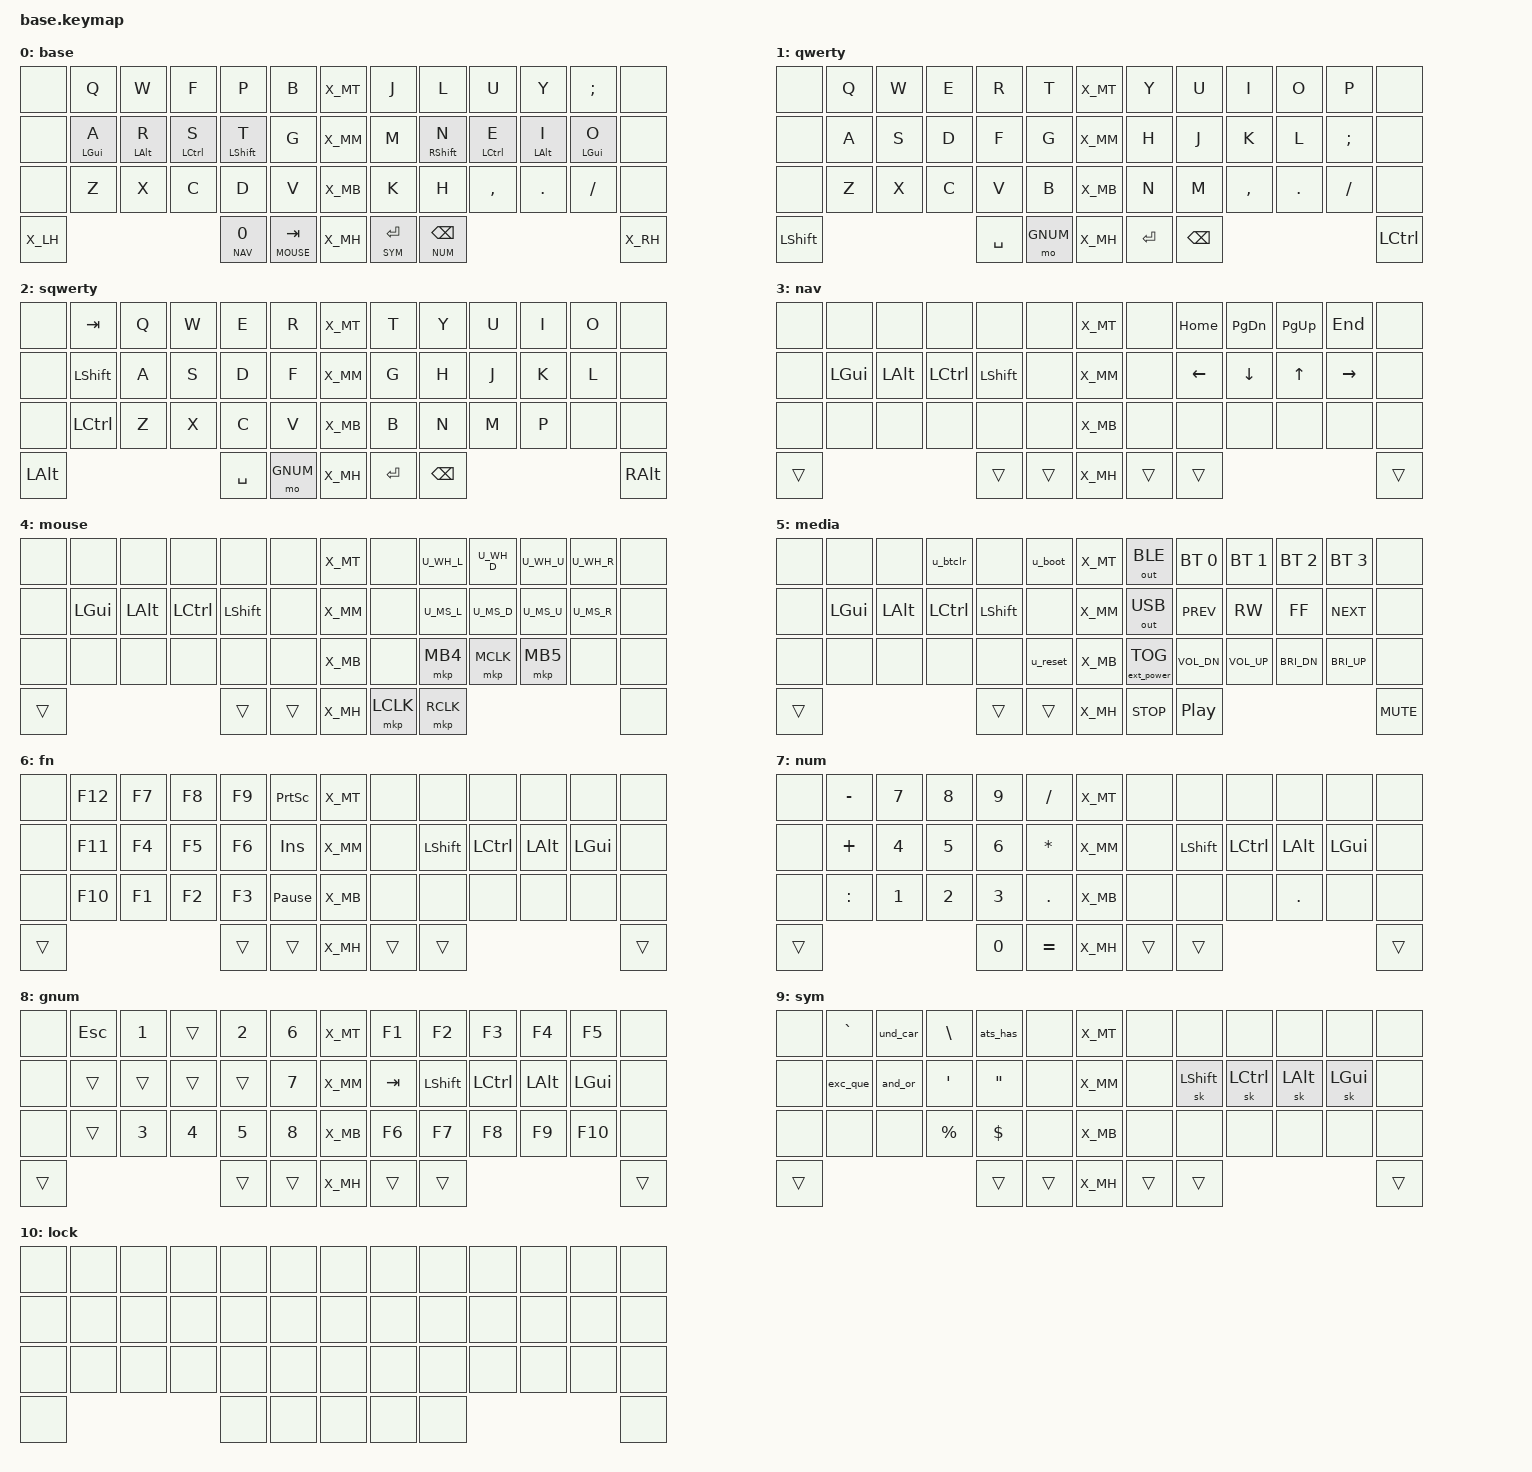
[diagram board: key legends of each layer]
#include <behaviors.dtsi>
#include <dt-bindings/zmk/keys.h>
#if CONFIG_WIRELESS
    #include <dt-bindings/zmk/bt.h>
    #define _BT_SEL_KEYS_ &bt BT_SEL 0 &bt BT_SEL 1 &bt BT_SEL 2 &bt BT_SEL 3 &bt BT_CLR
#else
    #define _BT_SEL_KEYS_ &trans &trans &trans &trans &trans
#endif

#include <dt-bindings/zmk/ext_power.h>
#include <dt-bindings/zmk/outputs.h>
#include "../zmk-nodefree-config/helper.h"
#include "../zmk-nodefree-config/international_chars/greek.dtsi"
#include "../zmk-nodefree-config/international_chars/german.dtsi"

#define DEF 0
#define QWERTY 1
#define SQWERTY 2
#define NAV 3
#define MOUSE 4
#define MEDIA 5
#define FN 6
#define NUM 7
#define GNUM 8
#define SYM 9
#define LOCK 10

#include "mouse.dtsi"
#include "extra_keys.h"

#define XXX &none
#define ___ &trans

/* Global settings */

#define QUICK_TAP_MS 175

&sk {  // sticky-key config
    release-after-ms = <900>;  // release after 0.6s
    quick-release;             // no double capitalization when rolling keys
};

&sl {  // sticky-layer config
    ignore-modifiers;          // allow chording sticky mods & layers
};

&lt {  // layer-tap config
    flavor = "balanced";
    tapping-term-ms = <200>;
    quick-tap-ms = <QUICK_TAP_MS>;
};

/* Homerow mods */

#define KEYS_L LT0 LT1 LT2 LT3 LT4 LM0 LM1 LM2 LM3 LM4 LB0 LB1 LB2 LB3 LB4  // left hand
#define KEYS_R RT0 RT1 RT2 RT3 RT4 RM0 RM1 RM2 RM3 RM4 RB0 RB1 RB2 RB3 RB4  // right hand
#define THUMBS LH2 LH1 LH0 RH0 RH1 RH2                                      // thumbs

#define MAKE_HRM(NAME, HOLD, TAP, TRIGGER_POS) \
    ZMK_BEHAVIOR(NAME, hold_tap, \
        flavor = "balanced"; \
        tapping-term-ms = <280>; \
        quick-tap-ms = <QUICK_TAP_MS>; \
        bindings = <HOLD>, <TAP>; \
        hold-trigger-key-positions = <TRIGGER_POS>; \
        hold-trigger-on-release; \
    )
MAKE_HRM(hml, &kp, &kp, KEYS_R THUMBS)  // left-hand HRMs
MAKE_HRM(hmr, &kp, &kp, KEYS_L THUMBS)  // right-hand HRMs

MAKE_HRM(hml_repeat, &kp, &key_repeat, KEYS_R THUMBS)  // used for HRM-combo
//MAKE_HRM(hmr_lpar_lt, &kp, &lpar_lt, KEYS_L THUMBS)    // "    "   "   "
//MAKE_HRM(hmr_rpar_gt, &kp, &rpar_gt, KEYS_L THUMBS)    // "    "   "   "

/* Caps-word, num-word and smart-mouse */

&caps_word {  // mods deactivate caps-word, requires PR #1441
    /delete-property/ ignore-modifiers;
};

// tap: num-word | double-tap: sticky num-layer | hold: num-layer
#define SMART_NUM &smart_num NUM 0
ZMK_BEHAVIOR(smart_num, hold_tap,
    flavor = "balanced";
    tapping-term-ms = <200>;
    quick-tap-ms = <QUICK_TAP_MS>;
    bindings = <&mo>, <&num_dance>;
)
ZMK_BEHAVIOR(num_dance, tap_dance,
    tapping-term-ms = <200>;
    bindings = <&num_word>, <&sl NUM>;  // reverse this for sticky-num on single tap
)
&num_word {  // num-word, requires PR #1441
    layers = <NUM>;
    continue-list = <BSPC DEL DOT COMMA PLUS MINUS STAR FSLH EQUAL COLON>;
};

// smart-mouse, requires PR #1366
ZMK_BEHAVIOR(smart_mouse, tri_state,
    bindings = <&tog MOUSE>, <&none>, <&tog MOUSE>;
    ignored-key-positions = <LT1 LT3 RT0 RT1 RT2 RT3 RT4 RM1 RM2 RM3 RB1 RB2 RB3 RH0 RH1>;
    ignored-layers = <MOUSE>;
)

/* Custom behaviors */

// mod_morphs
ZMK_BEHAVIOR(und_car, mod_morph,
    mods = <(MOD_LSFT|MOD_RSFT)>;
    bindings = <&kp UNDER>, <&kp CARET>;
)

ZMK_BEHAVIOR(and_or, mod_morph,
    mods = <(MOD_LSFT|MOD_RSFT)>;
    bindings = <&kp AMPS>, <&kp PIPE>;
)

ZMK_BEHAVIOR(tim_per, mod_morph,
    mods = <(MOD_LSFT|MOD_RSFT)>;
    bindings = <&kp STAR>, <&kp PRCNT>;
)

ZMK_BEHAVIOR(plu_min, mod_morph,
    mods = <(MOD_LSFT|MOD_RSFT)>;
    bindings = <&kp PLUS>, <&kp MINUS>;
)

ZMK_BEHAVIOR(exc_que, mod_morph,
    mods = <(MOD_LSFT|MOD_RSFT)>;
    bindings = <&kp EXCL>, <&kp QMARK>;
)

ZMK_BEHAVIOR(dap_sap, mod_morph,
    mods = <(MOD_LSFT|MOD_RSFT)>;
    bindings = <&kp DQT>, <&kp SQT>;
)

ZMK_BEHAVIOR(ats_has, mod_morph,
    mods = <(MOD_LSFT|MOD_RSFT)>;
    bindings = <&kp AT>, <&kp HASH>;
)
// /mod_morphs

// tap: space | shift + tap: dot -> space -> sticky shift | hold: activate layer
ZMK_BEHAVIOR(lt_spc, hold_tap,
    flavor = "balanced";
    tapping-term-ms = <200>;
    quick-tap-ms = <QUICK_TAP_MS>;
    bindings = <&mo>, <&spc_morph>;
)
ZMK_BEHAVIOR(spc_morph, mod_morph,
    bindings = <&kp SPACE>, <&dot_spc>;
    mods = <(MOD_LSFT|MOD_RSFT)>;
)
ZMK_BEHAVIOR(dot_spc, macro,
    wait-ms = <0>;
    tap-ms = <5>;
    bindings = <&kp DOT &kp SPACE &sk LSHFT>;
)
// double tap guards
ZMK_BEHAVIOR(u_btclr, tap_dance,
    tapping-term-ms = <200>;
    bindings = <&none>, <&bt BT_CLR>; 
)
ZMK_BEHAVIOR(u_boot, tap_dance,
    tapping-term-ms = <200>;
    bindings = <&none>, <&bootloader>; 
)
ZMK_BEHAVIOR(u_reset, tap_dance,
    tapping-term-ms = <200>;
    bindings = <&none>, <&sys_reset>; 
)



ZMK_BEHAVIOR(esc_alt, tap_dance,
    tapping-term-ms = <200>;
    bindings = <&kp ESC>, <&kp LALT>; 
)


#include "combos.dtsi"  // requires layer aliases and stuff

/* Keymap */

// ZMK_CONDITIONAL_LAYER(FN NUM, SYS)  // FN + NUM --> SYS use later :)

ZMK_LAYER(base,
//╭──────╮ ╭─────────────┬─────────────┬─────────────┬─────────────┬─────────────╮ ╭──────╮ ╭─────────────┬─────────────┬─────────────┬─────────────┬─────────────╮ ╭──────╮
    XXX      &kp Q         &kp W         &kp F         &kp P         &kp B           X_MT     &kp J         &kp L         &kp U         &kp Y         &kp SEMI        XXX 
//├──────┤ ├─────────────┼─────────────┼─────────────┼─────────────┼─────────────┤ ├──────┤ ├─────────────┼─────────────┼─────────────┼─────────────┼─────────────┤ ├──────┤
    XXX      &hml LGUI A   &hml LALT R   &hml LCTRL S  &hml LSHFT T  &kp G           X_MM     &kp M         &hmr RSHFT N  &hmr LCTRL E  &hmr LALT I   &hmr LGUI O     XXX 
//├──────┤ ├─────────────┼─────────────┼─────────────┼─────────────┼─────────────┤ ├──────┤ ├─────────────┼─────────────┼─────────────┼─────────────┼─────────────┤ ├──────┤
    XXX      &kp Z         &kp X         &kp C         &kp D         &kp V           X_MB     &kp K         &kp H         &kp COMMA     &kp DOT       &kp FSLH        XXX 
//├──────┤ ╰─────────────┼─────────────┴─────────────┼─────────────┼─────────────┤ ├──────┤ ├─────────────┼─────────────┼─────────────┴───────────────────────────╯ ├──────┤
    X_LH                                              &lt_spc NAV 0  &lt MOUSE TAB   X_MH     &lt SYM RET   &lt NUM BSPC                                              X_RH
//╰──────╯                                           ╰─────────────┴─────────────╯ ╰──────╯ ╰─────────────┴─────────────╯                                           ╰──────╯
)

ZMK_LAYER(qwerty,
//╭──────╮ ╭─────────────┬─────────────┬─────────────┬─────────────┬─────────────╮ ╭──────╮ ╭─────────────┬─────────────┬─────────────┬─────────────┬─────────────╮ ╭──────╮
    XXX      &kp Q         &kp W         &kp E         &kp R         &kp T           X_MT     &kp Y         &kp U         &kp I         &kp O         &kp P           XXX 
//├──────┤ ├─────────────┼─────────────┼─────────────┼─────────────┼─────────────┤ ├──────┤ ├─────────────┼─────────────┼─────────────┼─────────────┼─────────────┤ ├──────┤
    XXX      &kp A         &kp S         &kp D         &kp F         &kp G           X_MM     &kp H         &kp J         &kp K         &kp L         &kp SEMI        XXX 
//├──────┤ ├─────────────┼─────────────┼─────────────┼─────────────┼─────────────┤ ├──────┤ ├─────────────┼─────────────┼─────────────┼─────────────┼─────────────┤ ├──────┤
    XXX      &kp Z         &kp X         &kp C         &kp V         &kp B           X_MB     &kp N         &kp M         &kp COMMA     &kp DOT       &kp FSLH         XXX 
//├──────┤ ╰─────────────┼─────────────┴─────────────┼─────────────┼─────────────┤ ├──────┤ ├─────────────┼─────────────┼─────────────┴───────────────────────────╯ ├──────┤
    &kp LSHFT                                          &kp SPACE     &mo GNUM        X_MH      &kp RET      &kp BSPC                                                &kp LCTRL
//╰──────╯                                           ╰─────────────┴─────────────╯ ╰──────╯ ╰─────────────┴─────────────╯                                           ╰──────╯
)

ZMK_LAYER(sqwerty,
//╭──────╮ ╭─────────────┬─────────────┬─────────────┬─────────────┬─────────────╮ ╭──────╮ ╭─────────────┬─────────────┬─────────────┬─────────────┬─────────────╮ ╭──────╮
    XXX      &kp TAB       &kp Q         &kp W         &kp E         &kp R           X_MT     &kp T         &kp Y         &kp U         &kp I         &kp O           XXX 
//├──────┤ ├─────────────┼─────────────┼─────────────┼─────────────┼─────────────┤ ├──────┤ ├─────────────┼─────────────┼─────────────┼─────────────┼─────────────┤ ├──────┤
    XXX      &kp LSHFT     &kp A         &kp S         &kp D         &kp F           X_MM     &kp G         &kp H         &kp J         &kp K         &kp L           XXX 
//├──────┤ ├─────────────┼─────────────┼─────────────┼─────────────┼─────────────┤ ├──────┤ ├─────────────┼─────────────┼─────────────┼─────────────┼─────────────┤ ├──────┤
    XXX      &kp LCTRL     &kp Z         &kp X         &kp C         &kp V           X_MB     &kp B         &kp N         &kp M         &kp P         XXX             XXX
//├──────┤ ╰─────────────┼─────────────┴─────────────┼─────────────┼─────────────┤ ├──────┤ ├─────────────┼─────────────┼─────────────┴───────────────────────────╯ ├──────┤
    &kp LALT                                           &kp SPACE     &mo GNUM        X_MH      &kp RET      &kp BSPC                                                &kp RALT
//╰──────╯                                           ╰─────────────┴─────────────╯ ╰──────╯ ╰─────────────┴─────────────╯                                           ╰──────╯
)

ZMK_LAYER(nav,
//╭──────╮ ╭─────────────┬─────────────┬─────────────┬─────────────┬─────────────╮ ╭──────╮ ╭─────────────┬─────────────┬─────────────┬─────────────┬─────────────╮ ╭──────╮
    XXX      XXX           XXX           XXX           XXX           XXX             X_MT     XXX           &kp HOME      &kp PG_DN     &kp PG_UP     &kp END         XXX
//├──────┤ ├─────────────┼─────────────┼─────────────┼─────────────┼─────────────┤ ├──────┤ ├─────────────┼─────────────┼─────────────┼─────────────┼─────────────┤ ├──────┤
    XXX      &kp LGUI      &kp LALT      &kp LCTRL     &kp LSHFT     XXX             X_MM     XXX          &kp LEFT      &kp DOWN      &kp UP        &kp RIGHT       XXX
//├──────┤ ├─────────────┼─────────────┼─────────────┼─────────────┼─────────────┤ ├──────┤ ├─────────────┼─────────────┼─────────────┼─────────────┼─────────────┤ ├──────┤
    XXX      XXX           XXX           XXX           XXX           XXX             X_MB     XXX           XXX           XXX           XXX           XXX             XXX
//├──────┤ ╰─────────────┼─────────────┴─────────────┼─────────────┼─────────────┤ ├──────┤ ├─────────────┼─────────────┼─────────────┴───────────────────────────╯ ├──────┤
    ___                                                ___           ___             X_MH     ___           ___                                                       ___
//╰──────╯                                           ╰─────────────┴─────────────╯ ╰──────╯ ╰─────────────┴─────────────╯                                           ╰──────╯
)

ZMK_LAYER(mouse,
//╭──────╮ ╭─────────────┬─────────────┬─────────────┬─────────────┬─────────────╮ ╭──────╮ ╭─────────────┬─────────────┬─────────────┬─────────────┬─────────────╮ ╭──────╮
    XXX      XXX           XXX           XXX            XXX          XXX             X_MT     XXX           U_WH_L        U_WH_D        U_WH_U        U_WH_R          XXX
//├──────┤ ├─────────────┼─────────────┼─────────────┼─────────────┼─────────────┤ ├──────┤ ├─────────────┼─────────────┼─────────────┼─────────────┼─────────────┤ ├──────┤
    XXX      &kp LGUI      &kp LALT      &kp LCTRL     &kp LSHFT     XXX             X_MM     XXX           U_MS_L        U_MS_D        U_MS_U        U_MS_R          XXX 
//├──────┤ ├─────────────┼─────────────┼─────────────┼─────────────┼─────────────┤ ├──────┤ ├─────────────┼─────────────┼─────────────┼─────────────┼─────────────┤ ├─-────┤
    XXX      XXX           XXX           XXX           XXX           XXX             X_MB     XXX           &mkp MB4      &mkp MCLK      &mkp MB5     XXX             XXX 
//├──────┤ ╰─────────────┼─────────────┴─────────────┼─────────────┼─────────────┤ ├──────┤ ├─────────────┼─────────────┼─────────────┴───────────────────────────╯ ├──────┤
    ___                                                ___           ___             X_MH     &mkp LCLK     &mkp RCLK                                                 XXX
//╰──────╯                                           ╰─────────────┴─────────────╯ ╰──────╯ ╰─────────────┴─────────────╯                                           ╰──────╯
)

ZMK_LAYER(media,
//╭──────╮ ╭─────────────┬─────────────┬─────────────┬─────────────┬─────────────╮ ╭──────╮ ╭─────────────┬─────────────┬─────────────┬─────────────┬─────────────╮ ╭──────╮
    XXX      XXX           XXX           &u_btclr      XXX           &u_boot         X_MT     &out OUT_BLE  &bt BT_SEL 0  &bt BT_SEL 1  &bt BT_SEL 2  &bt BT_SEL 3    XXX 
//├──────┤ ├─────────────┼─────────────┼─────────────┼─────────────┼─────────────┤ ├──────┤ ├─────────────┼─────────────┼─────────────┼─────────────┼─────────────┤ ├──────┤
    XXX      &kp LGUI      &kp LALT      &kp LCTRL     &kp LSHFT     XXX             X_MM     &out OUT_USB  &kp C_PREV    &kp C_RW      &kp C_FF      &kp C_NEXT      XXX 
//├──────┤ ├─────────────┼─────────────┼─────────────┼─────────────┼─────────────┤ ├──────┤ ├─────────────┼─────────────┼─────────────┼─────────────┼─────────────┤ ├──────┤
    XXX      XXX           XXX           XXX           XXX           &u_reset      X_MB   &ext_power EP_TOG &kp C_VOL_DN &kp C_VOL_UP &kp C_BRI_DN    &kp C_BRI_UP    XXX 
//├──────┤ ╰─────────────┼─────────────┴─────────────┼─────────────┼─────────────┤ ├──────┤ ├─────────────┼─────────────┼─────────────┴───────────────────────────╯ ├──────┤
    ___                                                ___           ___             X_MH   &kp C_STOP      &kp C_PP                                               &kp C_MUTE  
//╰──────╯                                           ╰─────────────┴─────────────╯ ╰──────╯ ╰─────────────┴─────────────╯                                           ╰──────╯
)

ZMK_LAYER(fn,
//╭──────╮ ╭─────────────┬─────────────┬─────────────┬─────────────┬─────────────╮ ╭──────╮ ╭─────────────┬─────────────┬─────────────┬─────────────┬─────────────╮ ╭──────╮
    XXX      &kp F12       &kp F7        &kp F8        &kp F9        &kp PSCRN       X_MT     XXX           XXX           XXX           XXX           XXX             XXX 
//├──────┤ ├─────────────┼─────────────┼─────────────┼─────────────┼─────────────┤ ├──────┤ ├─────────────┼─────────────┼─────────────┼─────────────┼─────────────┤ ├──────┤
    XXX      &kp F11       &kp F4        &kp F5        &kp F6        &kp INS         X_MM     XXX           &kp LSHFT     &kp LCTRL     &kp LALT      &kp LGUI        XXX 
//├──────┤ ├─────────────┼─────────────┼─────────────┼─────────────┼─────────────┤ ├──────┤ ├─────────────┼─────────────┼─────────────┼─────────────┼─────────────┤ ├──────┤
    XXX      &kp F10       &kp F1        &kp F2        &kp F3        &kp PAUSE_BREAK X_MB     XXX           XXX           XXX           XXX           XXX             XXX 
//├──────┤ ╰─────────────┼─────────────┴─────────────┼─────────────┼─────────────┤ ├──────┤ ├─────────────┼─────────────┼─────────────┴───────────────────────────╯ ├──────┤
    ___                                                ___           ___             X_MH     ___           ___                                                       ___ 
//╰──────╯                                           ╰─────────────┴─────────────╯ ╰──────╯ ╰─────────────┴─────────────╯                                           ╰──────╯
)

ZMK_LAYER(num,
//╭──────╮ ╭─────────────┬─────────────┬─────────────┬─────────────┬─────────────╮ ╭──────╮ ╭─────────────┬─────────────┬─────────────┬─────────────┬─────────────╮ ╭──────╮
    XXX      &kp MINUS     &kp N7        &kp N8        &kp N9        &kp FSLH        X_MT     XXX           XXX           XXX           XXX           XXX             XXX 
//├──────┤ ├─────────────┼─────────────┼─────────────┼─────────────┼─────────────┤ ├──────┤ ├─────────────┼─────────────┼─────────────┼─────────────┼─────────────┤ ├──────┤
    XXX      &kp PLUS      &kp N4        &kp N5        &kp N6        &kp STAR        X_MM     XXX           &kp LSHFT     &kp LCTRL     &kp LALT      &kp LGUI         XXX 
//├──────┤ ├─────────────┼─────────────┼─────────────┼─────────────┼─────────────┤ ├──────┤ ├─────────────┼─────────────┼─────────────┼─────────────┼─────────────┤ ├──────┤
    XXX      &kp COLON     &kp N1        &kp N2        &kp N3        &kp DOT         X_MB     XXX           XXX           XXX           &kp DOT       XXX             XXX 
//├──────┤ ╰─────────────┼─────────────┴─────────────┼─────────────┼─────────────┤ ├──────┤ ├─────────────┼─────────────┼─────────────┴───────────────────────────╯ ├──────┤
    ___                                                &kp N0       &kp EQUAL        X_MH     ___           ___                                                       ___ 
//╰──────╯                                           ╰─────────────┴─────────────╯ ╰──────╯ ────────────┴─────────────╯                                           ╰──────╯
)

ZMK_LAYER(gnum,
//╭──────╮ ╭─────────────┬─────────────┬─────────────┬─────────────┬─────────────╮ ╭──────╮ ╭─────────────┬─────────────┬─────────────┬─────────────┬─────────────╮ ╭──────╮
    XXX      &kp ESC       &kp N1        ___           &kp N2        &kp N6          X_MT     &kp F1        &kp F2        &kp F3        &kp F4        &kp F5          XXX 
//├──────┤ ├─────────────┼─────────────┼─────────────┼─────────────┼─────────────┤ ├──────┤ ├─────────────┼─────────────┼─────────────┼─────────────┼─────────────┤ ├──────┤
    XXX      ___           ___           ___           ___           &kp N7          X_MM     &kp TAB       &kp LSHFT     &kp LCTRL     &kp LALT      &kp LGUI         XXX 
//├──────┤ ├─────────────┼─────────────┼─────────────┼─────────────┼─────────────┤ ├──────┤ ├─────────────┼─────────────┼─────────────┼─────────────┼─────────────┤ ├──────┤
    XXX      ___           &kp N3        &kp N4        &kp N5        &kp N8          X_MB     &kp F6        &kp F7        &kp F8        &kp F9        &kp F10         XXX 
//├──────┤ ╰─────────────┼─────────────┴─────────────┼─────────────┼─────────────┤ ├──────┤ ├─────────────┼─────────────┼─────────────┴───────────────────────────╯ ├──────┤
    ___                                                ___           ___             X_MH     ___           ___                                                       ___ 
//╰──────╯                                           ╰─────────────┴─────────────╯ ╰──────╯ ────────────┴─────────────╯                                           ╰──────╯
)

ZMK_LAYER(sym,
//╭──────╮ ╭─────────────┬─────────────┬─────────────┬─────────────┬─────────────╮ ╭──────╮ ╭─────────────┬─────────────┬─────────────┬─────────────┬─────────────╮ ╭──────╮
    XXX      &kp GRAVE     &und_car      &kp BSLH      &ats_has      XXX             X_MT     XXX           XXX           XXX           XXX           XXX             XXX 
//├──────┤ ├─────────────┼─────────────┼─────────────┼─────────────┼─────────────┤ ├──────┤ ├─────────────┼─────────────┼─────────────┼─────────────┼─────────────┤ ├──────┤
    XXX      &exc_que      &and_or       &kp SQT       &kp DQT       XXX             X_MM     XXX           &sk LSHFT     &sk LCTRL     &sk LALT      &sk LGUI         XXX 
//├──────┤ ├─────────────┼─────────────┼─────────────┼─────────────┼─────────────┤ ├──────┤ ├─────────────┼─────────────┼─────────────┼─────────────┼─────────────┤ ├──────┤
    XXX      XXX           XXX           &kp PRCNT     &kp DLLR      XXX             X_MB     XXX           XXX           XXX           XXX           XXX             XXX  
//├──────┤ ╰─────────────┼─────────────┴─────────────┼─────────────┼─────────────┤ ├──────┤ ├─────────────┼─────────────┼─────────────┴───────────────────────────╯ ├──────┤
    ___                                                ___           ___             X_MH     ___           ___                                                       ___ 
//╰──────╯                                           ╰─────────────┴─────────────╯ ╰──────╯ ╰─────────────┴─────────────╯                                           ╰──────╯
)

ZMK_LAYER(lock,
//╭──────╮ ╭─────────────┬─────────────┬─────────────┬─────────────┬─────────────╮ ╭──────╮ ╭─────────────┬─────────────┬─────────────┬─────────────┬─────────────╮ ╭──────╮
    XXX      XXX           XXX           XXX           XXX           XXX             XXX      XXX           XXX           XXX           XXX           XXX             XXX 
//├──────┤ ├─────────────┼─────────────┼─────────────┼─────────────┼─────────────┤ ├──────┤ ├─────────────┼─────────────┼─────────────┼─────────────┼─────────────┤ ├──────┤
    XXX      XXX           XXX           XXX           XXX           XXX             XXX      XXX           XXX           XXX           XXX           XXX             XXX 
//├──────┤ ├─────────────┼─────────────┼─────────────┼─────────────┼─────────────┤ ├──────┤ ├─────────────┼─────────────┼─────────────┼─────────────┼─────────────┤ ├──────┤
    XXX      XXX           XXX           XXX           XXX           XXX             XXX      XXX           XXX           XXX           XXX           XXX             XXX 
//├──────┤ ╰─────────────┼─────────────┴─────────────┼─────────────┼─────────────┤ ├──────┤ ├─────────────┼─────────────┼─────────────┴───────────────────────────╯ ├──────┤
    XXX                                                XXX           XXX             XXX      XXX           XXX                                                       XXX 
//╰──────╯                                           ╰─────────────┴─────────────╯ ╰──────╯ ╰─────────────┴─────────────╯                                           ╰──────╯
)
/* vim: set ft=c tw=174:*/
